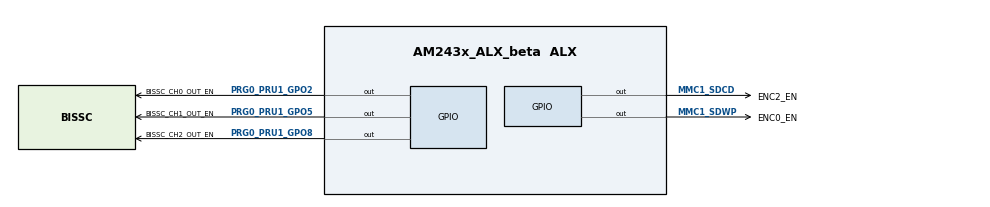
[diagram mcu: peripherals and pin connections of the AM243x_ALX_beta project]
/**
 * @cliArgs --device "AM243x_ALX_beta" --package "ALX" --part "ALX" --context "r5fss0-0" --product "MOTOR_CONTROL_SDK@09.01.00"
 * @versions {"tool":"1.18.0+3266"}
 */

/**
 * Import the modules used in this configuration.
 */
const gpio       = scripting.addModule("/drivers/gpio/gpio", {}, false);
const gpio1      = gpio.addInstance();
const gpio2      = gpio.addInstance();
const gpio3      = gpio.addInstance();
const gpio4      = gpio.addInstance();
const gpio5      = gpio.addInstance();
const gpio6      = gpio.addInstance();
const debug_log  = scripting.addModule("/kernel/dpl/debug_log");
const mpu_armv7  = scripting.addModule("/kernel/dpl/mpu_armv7", {}, false);
const mpu_armv71 = mpu_armv7.addInstance();
const mpu_armv72 = mpu_armv7.addInstance();
const mpu_armv73 = mpu_armv7.addInstance();
const mpu_armv74 = mpu_armv7.addInstance();
const mpu_armv75 = mpu_armv7.addInstance();
const bissc      = scripting.addModule("/position_sense/bissc", {}, false);
const bissc1     = bissc.addInstance();

/**
 * Write custom configuration values to the imported modules.
 */
debug_log.enableUartLog        = true;
debug_log.enableCssLog         = false;
debug_log.uartLog.$name        = "CONFIG_UART_CONSOLE";
debug_log.uartLog.UART.$assign = "USART0";

mpu_armv71.$name             = "CONFIG_MPU_REGION0";
mpu_armv71.size              = 31;
mpu_armv71.attributes        = "Device";
mpu_armv71.accessPermissions = "Supervisor RD+WR, User RD";
mpu_armv71.allowExecute      = false;

mpu_armv72.$name             = "CONFIG_MPU_REGION1";
mpu_armv72.size              = 15;
mpu_armv72.accessPermissions = "Supervisor RD+WR, User RD";

mpu_armv73.$name             = "CONFIG_MPU_REGION2";
mpu_armv73.baseAddr          = 0x41010000;
mpu_armv73.size              = 15;
mpu_armv73.accessPermissions = "Supervisor RD+WR, User RD";

mpu_armv74.$name             = "CONFIG_MPU_REGION3";
mpu_armv74.accessPermissions = "Supervisor RD+WR, User RD";
mpu_armv74.baseAddr          = 0x70000000;
mpu_armv74.size              = 21;

mpu_armv75.$name             = "CONFIG_MPU_REGION4";
mpu_armv75.baseAddr          = 0x60000000;
mpu_armv75.size              = 28;
mpu_armv75.accessPermissions = "Supervisor RD, User RD";

bissc1.$name                      = "CONFIG_BISSC0";
bissc1.Booster_Pack               = true;
bissc1.channel_2                  = true;
bissc1.Multi_Channel_Load_Share   = true;
bissc1.PRU_ICSSG0_PRU.$assign     = "PRU_ICSSG0_PRU1";
bissc1.PRU_ICSSG0_PRU.GPO4.$used  = false;
bissc1.PRU_ICSSG0_PRU.GPO3.$used  = false;
bissc1.PRU_ICSSG0_PRU.GPI14.$used = false;

bissc1.ENC1_EN           = gpio1;
gpio1.$name              = "ENC1_EN";
gpio1.GPIO.$assign       = "GPIO1";
gpio1.GPIO.gpioPin.pu_pd = "pu";
gpio1.GPIO.gpioPin.rx    = false;

bissc1.BISSC_CH0_OUT_EN    = gpio2;
gpio2.$name                = "BISSC_CH0_OUT_EN";
gpio2.GPIO.gpioPin.rx      = false;
gpio2.GPIO.gpioPin.$assign = "PRG0_PRU1_GPO2";

bissc1.BISSC_CH2_OUT_EN    = gpio3;
gpio3.$name                = "BISSC_CH2_OUT_EN";
gpio3.GPIO.gpioPin.rx      = false;
gpio3.GPIO.gpioPin.$assign = "PRG0_PRU1_GPO8";

bissc1.ENC2_EN             = gpio4;
gpio4.$name                = "ENC2_EN";
gpio4.GPIO.gpioPin.pu_pd   = "pu";
gpio4.GPIO.gpioPin.rx      = false;
gpio4.GPIO.gpioPin.$assign = "MMC1_SDCD";

bissc1.BISSC_CH1_OUT_EN    = gpio5;
gpio5.$name                = "BISSC_CH1_OUT_EN";
gpio5.GPIO.gpioPin.rx      = false;
gpio5.GPIO.gpioPin.$assign = "PRG0_PRU1_GPO5";

gpio6.$name                = "ENC0_EN";
gpio6.pinDir               = "OUTPUT";
bissc1.ENC0_EN             = gpio6;
gpio6.GPIO.gpioPin.$assign = "MMC1_SDWP";

const pruicss                            = scripting.addModule("/drivers/pruicss/pruicss", {}, false);
const pruicss1                           = pruicss.addInstance({}, false);
pruicss1.$name                           = "CONFIG_PRU_ICSS0";
bissc1.pru                               = pruicss1;
pruicss1.AdditionalICSSSettings[0].$name = "CONFIG_PRU_ICSS_IO0";

/**
 * Pinmux solution for unlocked pins/peripherals. This ensures that minor changes to the automatic solver in a future
 * version of the tool will not impact the pinmux you originally saw.  These lines can be completely deleted in order to
 * re-solve from scratch.
 */
debug_log.uartLog.UART.RXD.$suggestSolution  = "UART0_RXD";
debug_log.uartLog.UART.TXD.$suggestSolution  = "UART0_TXD";
bissc1.PRU_ICSSG0_PRU.GPO1.$suggestSolution  = "PRG0_PRU1_GPO1";
bissc1.PRU_ICSSG0_PRU.GPO0.$suggestSolution  = "PRG0_PRU1_GPO0";
bissc1.PRU_ICSSG0_PRU.GPI13.$suggestSolution = "PRG0_PRU1_GPO13";
bissc1.PRU_ICSSG0_PRU.GPO12.$suggestSolution = "PRG0_PRU1_GPO12";
bissc1.PRU_ICSSG0_PRU.GPO6.$suggestSolution  = "PRG0_PRU1_GPO6";
bissc1.PRU_ICSSG0_PRU.GPI11.$suggestSolution = "PRG0_PRU1_GPO11";
gpio1.GPIO.gpioPin.$suggestSolution          = "PRG0_PRU0_GPO0";
gpio2.GPIO.$suggestSolution                  = "GPIO1";
gpio3.GPIO.$suggestSolution                  = "GPIO1";
gpio4.GPIO.$suggestSolution                  = "GPIO1";
gpio5.GPIO.$suggestSolution                  = "GPIO1";
gpio6.GPIO.$suggestSolution                  = "GPIO1";
